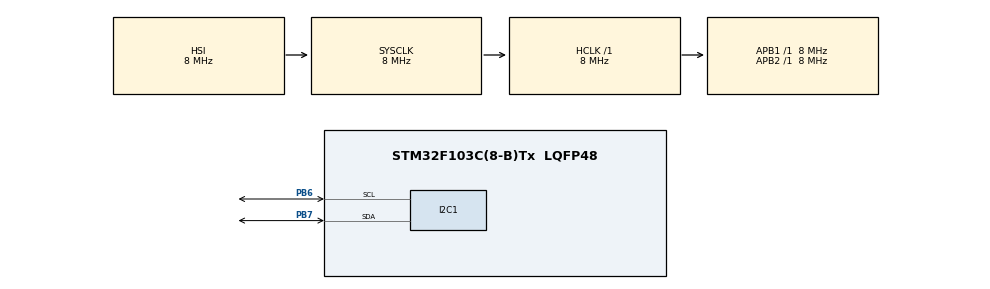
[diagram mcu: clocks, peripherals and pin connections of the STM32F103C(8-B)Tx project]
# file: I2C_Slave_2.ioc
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I2C1.OwnAddress=0x12
Mcu.Family=STM32F1
Mcu.Name=STM32F103C(8-B)Tx
Mcu.Package=LQFP48
NVIC.I2C1_ER_IRQn=true\:0\:0\:false\:false\:true\:true\:true\:true
NVIC.I2C1_EV_IRQn=true\:0\:0\:false\:false\:true\:true\:true\:true
NVIC.PriorityGroup=NVIC_PRIORITYGROUP_4
PA13.Mode=Serial_Wire
PA13.Signal=SYS_JTMS-SWDIO
PA14.Mode=Serial_Wire
PA14.Signal=SYS_JTCK-SWCLK
PB6.GPIO_Speed=GPIO_SPEED_FREQ_HIGH
PB6.Mode=I2C
PB6.Signal=I2C1_SCL
PB7.Mode=I2C
PB7.Signal=I2C1_SDA
PD0-OSC_IN.Mode=HSE-External-Oscillator
PD0-OSC_IN.Signal=RCC_OSC_IN
PD1-OSC_OUT.Mode=HSE-External-Oscillator
PD1-OSC_OUT.Signal=RCC_OSC_OUT
ProjectManager.HeapSize=0x200
ProjectManager.StackSize=0x400
ProjectManager.TargetToolchain=STM32CubeIDE
RCC.AHBFreq_Value=8000000
RCC.APB1Freq_Value=8000000
RCC.APB1TimFreq_Value=8000000
RCC.APB2Freq_Value=8000000
RCC.APB2TimFreq_Value=8000000
RCC.HCLKFreq_Value=8000000
RCC.PLLSourceVirtual=RCC_PLLSOURCE_HSE
RCC.SYSCLKFreq_VALUE=8000000
RCC.USBFreq_Value=16000000
board=custom

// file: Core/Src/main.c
/* USER CODE BEGIN Header */
/**
  ******************************************************************************
  * @file           : main.c
  * @brief          : Main program body
  ******************************************************************************
  * @attention
  *
  * Copyright (c) 2024 STMicroelectronics.
  * All rights reserved.
  *
  * This software is licensed under terms that can be found in the LICENSE file
  * in the root directory of this software component.
  * If no LICENSE file comes with this software, it is provided AS-IS.
  *
  ******************************************************************************
  */
/* USER CODE END Header */
#include "main.h"
#include "stm32f1xx_hal.h"
#include "stdio.h"
#include "stdint.h"
#include "math.h"
#include <float.h>
#include <string.h>

/* USER CODE BEGIN PD */
#define RxSIZE 5
#define MAX_REAL_NUMS 6 // Số lượng giá trị real_num tối đa mà mảng có thể chứa
/* USER CODE END PD */

I2C_HandleTypeDef hi2c1;

/* USER CODE BEGIN PV */

uint8_t RxData[5]; // mảng chứa toàn bộ data

double real_num;
 int32_t a = 0;
 uint8_t exponent = 0;
 uint64_t mu = 0;

double real_num_array[60]; // Khai báo mảng để lưu trữ các giá trị real_num
uint8_t real_num_count =0  ; // Biến đếm số lượng giá trị real_num đã lưu

/* USER CODE END PV */

void SystemClock_Config(void);
static void MX_GPIO_Init(void);
static void MX_I2C1_Init(void);
/* USER CODE BEGIN PFP */

void HAL_I2C_SlaveRxCpltCallback(I2C_HandleTypeDef *hi2c) {
    // Continue receiving data for the next transmission

    HAL_I2C_Slave_Receive_IT(hi2c, RxData, RxSIZE);
    // Concatenate RxData into a single 32-bit variable
    a = ((uint32_t)RxData[0] << 24) |
        ((uint32_t)RxData[1] << 16) |
        ((uint32_t)RxData[2] << 8) |
        (uint32_t)RxData[3];

    // Get the exponent value from RxData
    exponent = RxData[4];

    // Calculate mu and real_num values
    mu = pow(10, exponent);
    real_num = (double)((double)a/ mu);

    real_num_array[real_num_count] = real_num;
    real_num_count++;

}

//    // Lưu giá trị real_num vào mảng
//    if (real_num_count < MAX_REAL_NUMS) {
//        real_num_array[real_num_count] = real_num;
//        real_num_count++;
////        memset( RxData, 0, sizeof( RxData));// Reset các phần tử của RxData về 0
//        RxData[0] =0;
//		RxData[1] =0;
//		RxData[2] =0;
//		RxData[3] =0;
//		RxData[4] =0;
//	    a= 0 ;
//	    mu = 0;
//	    real_num=0;
//	    exponent =0;
//
//    }
//
//    else{
//        // Nếu đã đủ 6 giá trị, reset lại tất cả các phần tử của mảng
//
////    	memset(real_num_array, 0, sizeof(real_num_array));
//
//    	real_num_array[0] =0;
//    	real_num_array[1] =0;
//    	real_num_array[2] =0;
//    	real_num_array[3] =0;
//    	real_num_array[4] =0;
//    	real_num_array[5] =0;
//    	real_num_count = 0; // Đặt lại biến đếm về 0
//    }

/* USER CODE END PFP */

int main(void)
{

  /* MCU Configuration--------------------------------------------------------*/

  /* Reset of all peripherals, Initializes the Flash interface and the Systick. */
  HAL_Init();

  /* Configure the system clock */
  SystemClock_Config();

  /* Initialize all configured peripherals */
  MX_GPIO_Init();
  MX_I2C1_Init();
  /* USER CODE BEGIN 2 */

//  HAL_I2C_SlaveRxCpltCallback(&hi2c1);

  // Gọi hàm chuyển đổi

  /* USER CODE END 2 */

  /* Infinite loop */
  while (1)
  {

    /* USER CODE BEGIN 3 */
	    // Bắt đầu nhận dữ liệu từ master
//  HAL_I2C_Slave_Receive_IT(&hi2c1, RxData, RxSIZE);

  }
  /* USER CODE END 3 */
}

void SystemClock_Config(void)
{
  RCC_OscInitTypeDef RCC_OscInitStruct = {0};
  RCC_ClkInitTypeDef RCC_ClkInitStruct = {0};

  /** Initializes the RCC Oscillators according to the specified parameters
  * in the RCC_OscInitTypeDef structure.
  */
  RCC_OscInitStruct.OscillatorType = RCC_OSCILLATORTYPE_HSI;
  RCC_OscInitStruct.HSIState = RCC_HSI_ON;
  RCC_OscInitStruct.HSICalibrationValue = RCC_HSICALIBRATION_DEFAULT;
  RCC_OscInitStruct.PLL.PLLState = RCC_PLL_NONE;
  if (HAL_RCC_OscConfig(&RCC_OscInitStruct) != HAL_OK)
  {
    Error_Handler();
  }

  /** Initializes the CPU, AHB and APB buses clocks
  */
  RCC_ClkInitStruct.ClockType = RCC_CLOCKTYPE_HCLK|RCC_CLOCKTYPE_SYSCLK
                              |RCC_CLOCKTYPE_PCLK1|RCC_CLOCKTYPE_PCLK2;
  RCC_ClkInitStruct.SYSCLKSource = RCC_SYSCLKSOURCE_HSI;
  RCC_ClkInitStruct.AHBCLKDivider = RCC_SYSCLK_DIV1;
  RCC_ClkInitStruct.APB1CLKDivider = RCC_HCLK_DIV1;
  RCC_ClkInitStruct.APB2CLKDivider = RCC_HCLK_DIV1;

  if (HAL_RCC_ClockConfig(&RCC_ClkInitStruct, FLASH_LATENCY_0) != HAL_OK)
  {
    Error_Handler();
  }
}

static void MX_I2C1_Init(void)
{

  hi2c1.Instance = I2C1;
  hi2c1.Init.ClockSpeed = 100000;
  hi2c1.Init.DutyCycle = I2C_DUTYCYCLE_2;
  hi2c1.Init.OwnAddress1 = 36;
  hi2c1.Init.AddressingMode = I2C_ADDRESSINGMODE_7BIT;
  hi2c1.Init.DualAddressMode = I2C_DUALADDRESS_DISABLE;
  hi2c1.Init.OwnAddress2 = 0;
  hi2c1.Init.GeneralCallMode = I2C_GENERALCALL_DISABLE;
  hi2c1.Init.NoStretchMode = I2C_NOSTRETCH_DISABLE;
  if (HAL_I2C_Init(&hi2c1) != HAL_OK)
  {
    Error_Handler();
  }

}

static void MX_GPIO_Init(void)
{

  /* GPIO Ports Clock Enable */
  __HAL_RCC_GPIOD_CLK_ENABLE();
  __HAL_RCC_GPIOA_CLK_ENABLE();
  __HAL_RCC_GPIOB_CLK_ENABLE();

}

void Error_Handler(void)
{
  __disable_irq();
  while (1)
  {
  }
}
